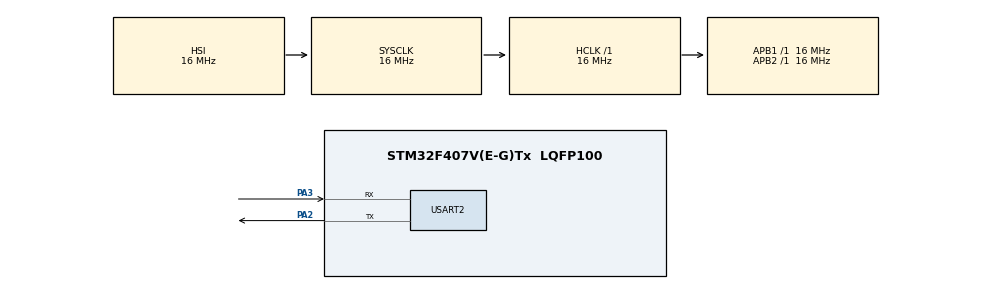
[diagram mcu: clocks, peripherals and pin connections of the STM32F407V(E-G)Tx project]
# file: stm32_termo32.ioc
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Mcu.Family=STM32F4
Mcu.Name=STM32F407V(E-G)Tx
Mcu.Package=LQFP100
NVIC.PriorityGroup=NVIC_PRIORITYGROUP_4
PA2.Mode=Asynchronous
PA2.Signal=USART2_TX
PA3.Mode=Asynchronous
PA3.Signal=USART2_RX
ProjectManager.HeapSize=0x200
ProjectManager.StackSize=0x400
ProjectManager.TargetToolchain=STM32CubeIDE
RCC.AHBFreq_Value=16000000
RCC.APB1Freq_Value=16000000
RCC.APB2Freq_Value=16000000
RCC.CortexFreq_Value=16000000
RCC.HSE_VALUE=25000000
RCC.HSI_VALUE=16000000
RCC.LSE_VALUE=32768
RCC.SYSCLKFreq_VALUE=16000000
RCC.VCOOutputFreq_Value=192000000
USART2.VirtualMode=VM_ASYNC
board=custom

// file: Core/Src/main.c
/* USER CODE BEGIN Header */
/**
 ******************************************************************************
 * @file           : main.c
 * @brief          : Main program body
 ******************************************************************************
 * @attention
 *
 * Copyright (c) 2026 STMicroelectronics.
 * All rights reserved.
 *
 * This software is licensed under terms that can be found in the LICENSE file
 * in the root directory of this software component.
 * If no LICENSE file comes with this software, it is provided AS-IS.
 *
 ******************************************************************************
 */
/* USER CODE END Header */
#include "main.h"

/* USER CODE BEGIN Includes */
#include <string.h>
/* USER CODE END Includes */

UART_HandleTypeDef huart2;

void SystemClock_Config(void);
static void MX_GPIO_Init(void);
static void MX_USART2_UART_Init(void);

/* USER CODE BEGIN 0 */
#include "images.h"

typedef enum {
	FONT_12x24 = 0, FONT_9x24 = 1, FONT_9x17 = 2, FONT_8x16 = 3, FONT_16x18 = 4
} FontType_t;

void set_font(uint8_t selected_font) {
	uint8_t command_font_select[] = { 0x1b, 0x4d, selected_font };
	HAL_UART_Transmit(&huart2, command_font_select, 3, 100);

}
/* USER CODE END 0 */

int main(void) {

	/* MCU Configuration--------------------------------------------------------*/

	/* Reset of all peripherals, Initializes the Flash interface and the Systick. */
	HAL_Init();

	/* Configure the system clock */
	SystemClock_Config();

	/* Initialize all configured peripherals */
	MX_GPIO_Init();
	MX_USART2_UART_Init();
	/* USER CODE BEGIN 2 */

	// INITIALIZE
	uint8_t command_init[] = { 0x1B, 0x40 };
	HAL_UART_Transmit(&huart2, command_init, 2, 1000);
	HAL_Delay(100);
	//56 szerokości, 0 mode
	uint8_t command_image_mode[] = { 0x1B, 0x2A, 0x00, 56, 0 };
	HAL_UART_Transmit(&huart2, command_image_mode, 5, 1000);

	//darth vader low quality bardzo 16x28
	const uint8_t epd_bitmap_darth_vader [] = {
		0xff, 0xff, 0xff, 0xff, 0xff, 0xff, 0xff, 0xff, 0xff, 0x3f, 0x00, 0x00, 0x01, 0x07, 0x6f, 0xff,
		0xff, 0xff, 0xff, 0xff, 0xe1, 0x73, 0xf3, 0xf3, 0xfb, 0xfd, 0xfd, 0xfd, 0xff, 0xff, 0xff, 0xff,
		0xff, 0xff, 0xff, 0xff, 0xfc, 0x90, 0x80, 0xb8, 0xf8, 0x98, 0xfd, 0xf8, 0xfd, 0xfb, 0xff, 0xff,
		0xff, 0xff, 0x0f, 0x0f, 0x07, 0x07, 0x01, 0x00
	};
	uint8_t image_size = sizeof(epd_bitmap_darth_vader) / sizeof(uint8_t);
	HAL_UART_Transmit(&huart2, epd_bitmap_darth_vader, image_size, 1000);

	uint8_t command[] = {
	  0x1B, 0x33, 0x00, // odtęp pomiędzy - zero
	  0x0A				//nowa linia
	};
	uint8_t size = sizeof(command) / sizeof(uint8_t);
	HAL_UART_Transmit(&huart2, command, size, 100);

	/*   TESTOWANIE KROPECZEK

	 // SET
	 for(int i = 0; i < 5; i++){
	 set_font(i);
	 char text_tell_font[] = "Aktualny font numer: ";
	 HAL_UART_Transmit(&huart2, (uint8_t*) text_tell_font, strlen(text_tell_font), 1000);
	 uint8_t font_number = '0' + i;
	 HAL_UART_Transmit(&huart2, (uint8_t*) &font_number, 1, 1000);
	 char LF = '\n';
	 HAL_UART_Transmit(&huart2, (uint8_t*)&LF, 1, 1000);

	 char text_test[] = "--- - - -_ _ _ __ . . . ...\n";
	 HAL_UART_Transmit(&huart2, (uint8_t*) text_test, strlen(text_test), 1000);
	 }

	 */

	/* USER CODE END 2 */

	/* Infinite loop */
	while (1) {

	}
}

void SystemClock_Config(void) {
	RCC_OscInitTypeDef RCC_OscInitStruct = { 0 };
	RCC_ClkInitTypeDef RCC_ClkInitStruct = { 0 };

	/** Configure the main internal regulator output voltage
	 */
	__HAL_RCC_PWR_CLK_ENABLE();
	__HAL_PWR_VOLTAGESCALING_CONFIG(PWR_REGULATOR_VOLTAGE_SCALE1);

	/** Initializes the RCC Oscillators according to the specified parameters
	 * in the RCC_OscInitTypeDef structure.
	 */
	RCC_OscInitStruct.OscillatorType = RCC_OSCILLATORTYPE_HSI;
	RCC_OscInitStruct.HSIState = RCC_HSI_ON;
	RCC_OscInitStruct.HSICalibrationValue = RCC_HSICALIBRATION_DEFAULT;
	RCC_OscInitStruct.PLL.PLLState = RCC_PLL_NONE;
	if (HAL_RCC_OscConfig(&RCC_OscInitStruct) != HAL_OK) {
		Error_Handler();
	}

	/** Initializes the CPU, AHB and APB buses clocks
	 */
	RCC_ClkInitStruct.ClockType = RCC_CLOCKTYPE_HCLK | RCC_CLOCKTYPE_SYSCLK
			| RCC_CLOCKTYPE_PCLK1 | RCC_CLOCKTYPE_PCLK2;
	RCC_ClkInitStruct.SYSCLKSource = RCC_SYSCLKSOURCE_HSI;
	RCC_ClkInitStruct.AHBCLKDivider = RCC_SYSCLK_DIV1;
	RCC_ClkInitStruct.APB1CLKDivider = RCC_HCLK_DIV1;
	RCC_ClkInitStruct.APB2CLKDivider = RCC_HCLK_DIV1;

	if (HAL_RCC_ClockConfig(&RCC_ClkInitStruct, FLASH_LATENCY_0) != HAL_OK) {
		Error_Handler();
	}
}

static void MX_USART2_UART_Init(void) {

	huart2.Instance = USART2;
	huart2.Init.BaudRate = 9600;
	huart2.Init.WordLength = UART_WORDLENGTH_8B;
	huart2.Init.StopBits = UART_STOPBITS_1;
	huart2.Init.Parity = UART_PARITY_NONE;
	huart2.Init.Mode = UART_MODE_TX_RX;
	huart2.Init.HwFlowCtl = UART_HWCONTROL_NONE;
	huart2.Init.OverSampling = UART_OVERSAMPLING_16;
	if (HAL_UART_Init(&huart2) != HAL_OK) {
		Error_Handler();
	}

}

static void MX_GPIO_Init(void) {

	/* GPIO Ports Clock Enable */
	__HAL_RCC_GPIOA_CLK_ENABLE();

}

void Error_Handler(void) {
	__disable_irq();
	while (1) {
	}
}
